LIN_description_file ;

LIN_protocol_version = "2.2";
LIN_language_version = "2.2";
LIN_speed = 19.2 kbps;
Channel_name = "DB2";

Nodes {
  Master: DCM, 5.0 ms, 0.2 ms;
  Slaves: LSM;
}

Signals {
  BackliteBri: 8, 0, DCM, LSM;
  LSM_ResponseError: 1, 0, LSM, DCM;
  ReFogLamp: 1, 0, LSM, DCM;
  DshbBri: 8, 0, LSM, DCM;
  PrkgLiMod: 1, 0, LSM, DCM;
  LoBeamMod: 1, 0, LSM, DCM;
  FrntFogLamp: 1, 0, LSM, DCM;
  LampOffMod: 1, 0, LSM, DCM;
  AutHdLiCtrlMod: 1, 0, LSM, DCM;
  LiSwtFailr: 1, 0, LSM, DCM;
}

Frames {
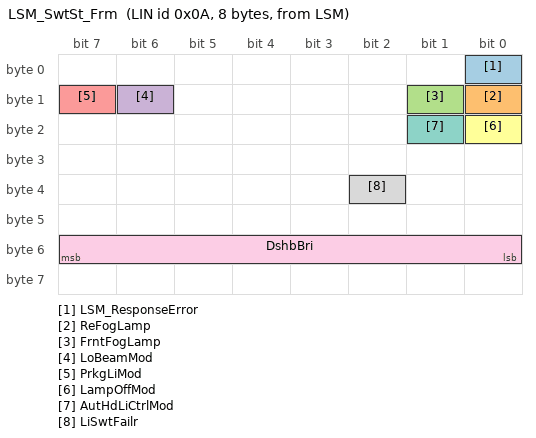
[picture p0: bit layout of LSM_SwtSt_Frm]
  LSM_SwtSt_Frm: 0x0A, LSM, 8 {
      LSM_ResponseError, 0;
    ReFogLamp, 8;
    FrntFogLamp, 9;
    LoBeamMod, 14;
    PrkgLiMod, 15;
    LampOffMod, 16;
    AutHdLiCtrlMod, 17;
    LiSwtFailr, 34;
    DshbBri, 48;
}
  DCM_BackliteCtrl_Frm: 0x2B, DCM, 4 {
    BackliteBri, 8;
}
}

Node_attributes {
  LSM {
        LIN_protocol = "2.2";
        configured_NAD = 0x21;
    product_id = 0x4E4E, 0x4553, 1;
    response_error = LSM_ResponseError;
        P2_min = 150 ms;
        ST_min = 50 ms;
    configurable_frames {
    LSM_SwtSt_Frm;
    DCM_BackliteCtrl_Frm;
    }
  }
}

Schedule_tables {
  Table1 {
    LSM_SwtSt_Frm delay 20 ms;
    DCM_BackliteCtrl_Frm delay 20 ms;
  }
}

Signal_encoding_types {
  LiBri_CompuMethod {
    physical_value, 0 ,0 ,0.3937 ,0 ,"%";
    logical_value, 255 ,"ERROR";
    logical_value, 0 ,"OFF";
  }
  LiSwtMod_CompuMethod {
    logical_value, 0 ,"LISWMOD_ON";
    logical_value, 1 ,"LISWMOD_OFF";
  }
  FogLamp_CompuMethod {
    logical_value, 1 ,"LAMP_ON";
    logical_value, 0 ,"LAMP_OFF";
  }
  LiSwtFailr_CompuMethod {
    logical_value, 0 ,"LISWT_NORML_ST";
    logical_value, 1 ,"LISWT_FAILR_ST";
  }
}

Signal_representation {
  LiBri_CompuMethod: BackliteBri, DshbBri;
  LiSwtMod_CompuMethod: PrkgLiMod, LoBeamMod, LampOffMod, AutHdLiCtrlMod;
  FogLamp_CompuMethod: FrntFogLamp, ReFogLamp;
  LiSwtFailr_CompuMethod: LiSwtFailr;
}
